# N32G05x register map
Vendor: Nationstech Ltd.; File version: 1.0
Registers are 32-bit, read-write, reset 0x0 unless marked. A register's access mark holds for its fields unless they carry their own. Offsets are from the block's base; [hi:lo] are bit positions; {n}, {i} and the like mark numbered series.

## SPI1 — Serial peripheral interface
Base 0x40012000
Same registers: SPI3 0x40014000, SPI2 0x40014400
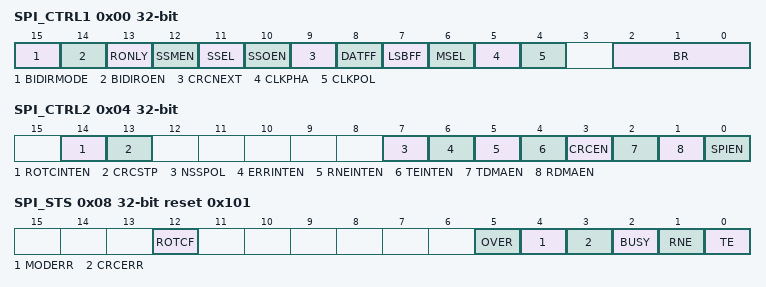
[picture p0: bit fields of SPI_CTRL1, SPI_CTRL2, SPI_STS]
0x00 SPI_CTRL1
  [15] BIDIRMODE
  [14] BIDIROEN
  [13] RONLY
  [12] SSMEN
  [11] SSEL
  [10] SSOEN — SSEL
  [9] CRCNEXT
  [8] DATFF
  [7] LSBFF
  [6] MSEL
  [5] CLKPHA
  [4] CLKPOL
  [2:0] BR
0x04 SPI_CTRL2
  [14] ROTCINTEN, [13] CRCSTP, [7] NSSPOL, [6] ERRINTEN, [5] RNEINTEN, [4] TEINTEN, [3] CRCEN, [2] TDMAEN, [1] RDMAEN, [0] SPIEN
0x08 SPI_STS reset 0x101
  [12] ROTCF, [5] OVER, [4] MODERR, [3] CRCERR, [2] BUSY, [1] RNE, [0] TE
0x0C SPI_DAT
  [15:0] DAT
0x10 SPI_CRCTDAT
  [15:0] CRCTDAT
0x14 SPI_CRCRDAT
  [15:0] CRCRDAT
0x18 SPI_CRCPOLY
  [15:0] CRCPOLY
0x38 SPI_CTRL3
  [3:0] DELAYTIME

## TIM1 — Advanced timer
Base 0x40012C00
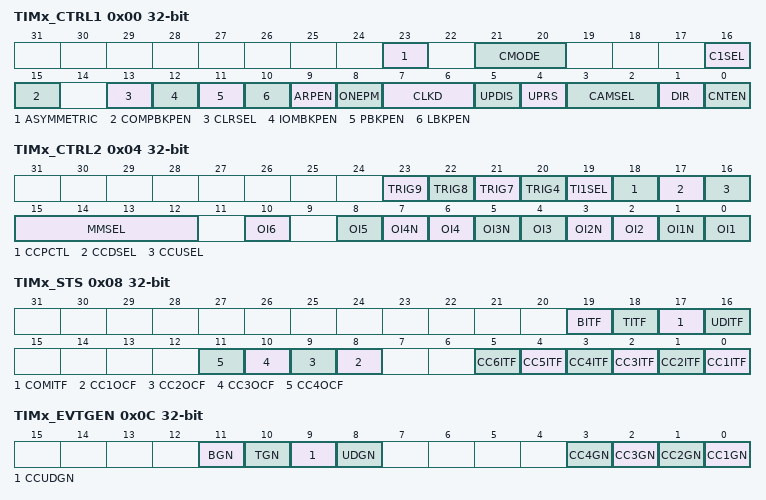
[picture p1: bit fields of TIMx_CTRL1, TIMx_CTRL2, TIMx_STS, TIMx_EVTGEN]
0x00 TIMx_CTRL1 (reset mask 0x38FFF)
  [23] ASYMMETRIC, [21:20] CMODE, [16] C1SEL, [15] COMPBKPEN, [13] CLRSEL, [12] IOMBKPEN, [11] PBKPEN, [10] LBKPEN, [9] ARPEN, [8] ONEPM, [7:6] CLKD, [5] UPDIS, [4] UPRS, [3:2] CAMSEL, [1] DIR, [0] CNTEN
0x04 TIMx_CTRL2 (reset mask 0x57FFD)
  [23] TRIG9, [22] TRIG8, [21] TRIG7, [20] TRIG4, [19] TI1SEL, [18] CCPCTL, [17] CCDSEL, [16] CCUSEL, [15:12] MMSEL, [2n-2] OI{n} (n=1..6), [2n-1] OI{n}N (n=1..4)
0x08 TIMx_STS
  [19] BITF, [18] TITF, [17] COMITF, [16] UDITF, [n+7] CC{n}OCF (n=1..4), [n-1] CC{n}ITF (n=1..6)
0x0C TIMx_EVTGEN
  [11] BGN, [10] TGN, [9] CCUDGN, [8] UDGN, [n-1] CC{n}GN (n=1..4)
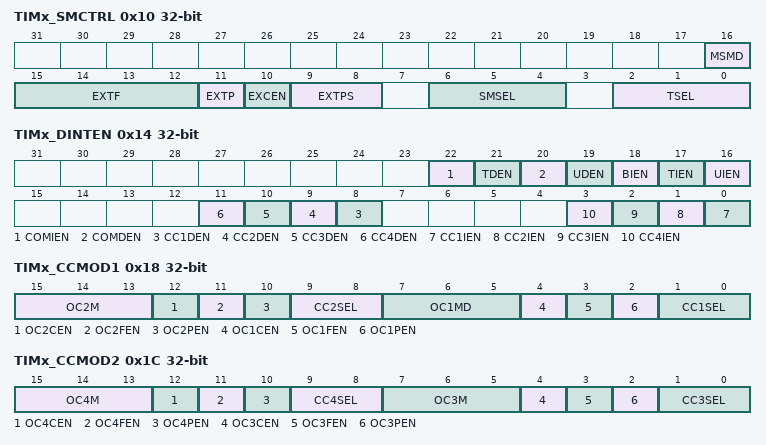
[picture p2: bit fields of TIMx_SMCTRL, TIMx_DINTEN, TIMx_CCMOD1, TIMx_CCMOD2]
0x10 TIMx_SMCTRL
  [16] MSMD, [15:12] EXTF, [11] EXTP, [10] EXCEN, [9:8] EXTPS, [6:4] SMSEL, [2:0] TSEL
0x14 TIMx_DINTEN
  [22] COMIEN, [21] TDEN, [20] COMDEN, [19] UDEN, [18] BIEN, [17] TIEN, [16] UIEN, [n+7] CC{n}DEN (n=1..4), [n-1] CC{n}IEN (n=1..4)
0x18 TIMx_CCMOD1
  [15:13] OC2M
  [12] OC2CEN
  [11] OC2FEN
  [10] OC2PEN
  [9:8] CC2SEL
  [7:5] OC1MD — OC1M
  [4] OC1CEN
  [3] OC1FEN
  [2] OC1PEN
  [1:0] CC1SEL
0x1C TIMx_CCMOD2
  [15:13] OC4M, [12] OC4CEN, [11] OC4FEN, [10] OC4PEN, [9:8] CC4SEL, [7:5] OC3M, [4] OC3CEN, [3] OC3FEN, [2] OC3PEN, [1:0] CC3SEL
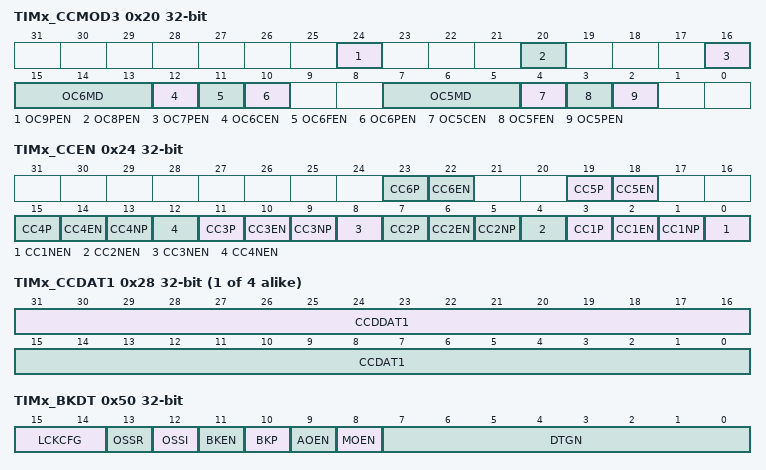
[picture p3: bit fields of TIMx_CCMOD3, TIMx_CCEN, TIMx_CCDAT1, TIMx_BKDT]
0x20 TIMx_CCMOD3
  [24] OC9PEN, [20] OC8PEN, [16] OC7PEN, [15:13] OC6MD, [12] OC6CEN, [11] OC6FEN, [10] OC6PEN, [7:5] OC5MD, [4] OC5CEN, [3] OC5FEN, [2] OC5PEN
0x24 TIMx_CCEN
  [4n-1] CC{n}P (n=1..6), [4n-2] CC{n}EN (n=1..6), [4n-3] CC{n}NP (n=1..4), [4n-4] CC{n}NEN (n=1..4)
{0x24+4i} TIMx_CCDAT{i} (i=1..4)
  [31:16] CCDDAT{i}, [15:0] CCDAT{i}
0x38 TIMx_CCDAT5
  [15:0] CCDAT5
0x3C TIMx_CCDAT6
  [15:0] CCDAT6
0x40 TIMx_PSC
  [15:0] PSC
0x44 TIMx_AR reset 0xFFFF
  [15:0] AR
0x48 TIMx_CNT
  [15:0] CNT
0x4C TIMx_REPCNT
  [7:0] REPCNT
0x50 TIMx_BKDT
  [15:14] LCKCFG, [13] OSSR, [12] OSSI, [11] BKEN, [10] BKP, [9] AOEN, [8] MOEN, [7:0] DTGN
{0x38+4i} TIMx_CCDAT{i} (i=7..9)
  [15:0] CCDAT{i}
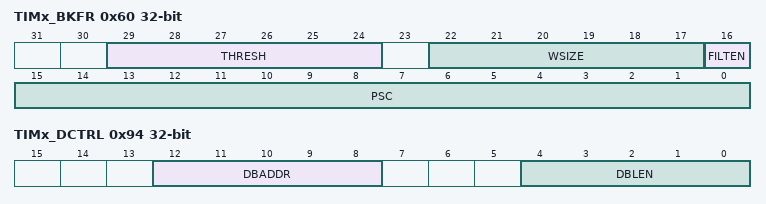
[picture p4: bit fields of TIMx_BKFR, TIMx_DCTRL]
0x60 TIMx_BKFR
  [29:24] THRESH, [22:17] WSIZE, [16] FILTEN, [15:0] PSC
0x94 TIMx_DCTRL
  [12:8] DBADDR, [4:0] DBLEN
0x98 TIMx_DADDR
  [15:0] BURST

## TIM2 — General purpose timer
Base 0x40013400
Same registers: TIM4 0x40012400, TIM5 0x40012800, TIM3 0x40013000
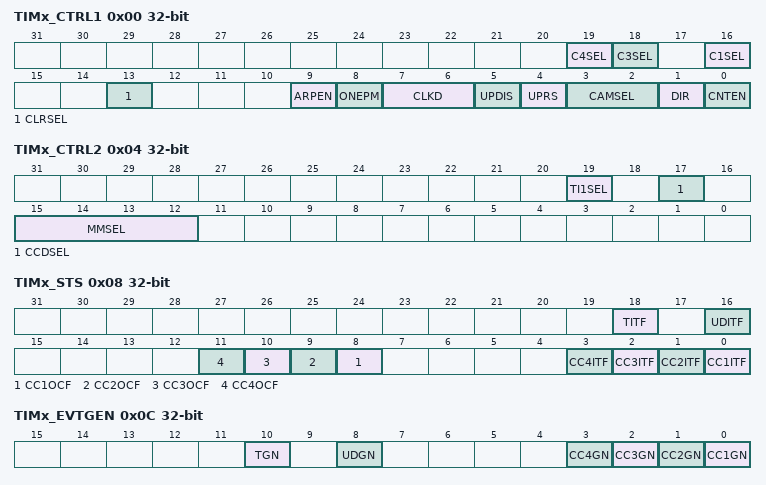
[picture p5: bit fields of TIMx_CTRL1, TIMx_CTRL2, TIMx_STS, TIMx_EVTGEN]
0x00 TIMx_CTRL1
  [19] C4SEL, [18] C3SEL, [16] C1SEL, [13] CLRSEL, [9] ARPEN, [8] ONEPM, [7:6] CLKD, [5] UPDIS, [4] UPRS, [3:2] CAMSEL, [1] DIR, [0] CNTEN
0x04 TIMx_CTRL2
  [19] TI1SEL, [17] CCDSEL, [15:12] MMSEL
0x08 TIMx_STS
  [18] TITF, [16] UDITF, [n+7] CC{n}OCF (n=1..4), [n-1] CC{n}ITF (n=1..4)
0x0C TIMx_EVTGEN
  [10] TGN, [8] UDGN, [n-1] CC{n}GN (n=1..4)
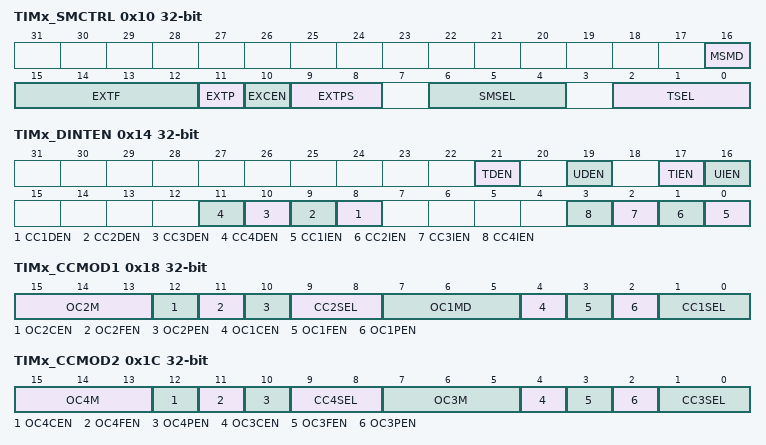
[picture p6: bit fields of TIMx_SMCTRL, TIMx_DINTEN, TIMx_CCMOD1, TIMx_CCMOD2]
0x10 TIMx_SMCTRL
  [16] MSMD, [15:12] EXTF, [11] EXTP, [10] EXCEN, [9:8] EXTPS, [6:4] SMSEL, [2:0] TSEL
0x14 TIMx_DINTEN
  [21] TDEN, [19] UDEN, [17] TIEN, [16] UIEN, [n+7] CC{n}DEN (n=1..4), [n-1] CC{n}IEN (n=1..4)
0x18 TIMx_CCMOD1
  [15:13] OC2M
  [12] OC2CEN
  [11] OC2FEN
  [10] OC2PEN
  [9:8] CC2SEL
  [7:5] OC1MD — OC1M
  [4] OC1CEN
  [3] OC1FEN
  [2] OC1PEN
  [1:0] CC1SEL
0x1C TIMx_CCMOD2
  [15:13] OC4M, [12] OC4CEN, [11] OC4FEN, [10] OC4PEN, [9:8] CC4SEL, [7:5] OC3M, [4] OC3CEN, [3] OC3FEN, [2] OC3PEN, [1:0] CC3SEL
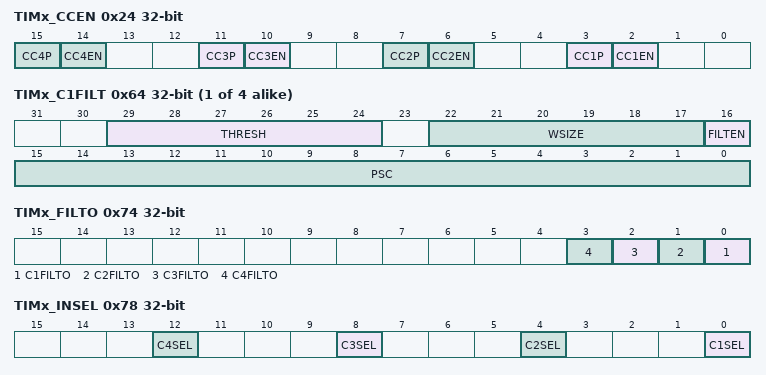
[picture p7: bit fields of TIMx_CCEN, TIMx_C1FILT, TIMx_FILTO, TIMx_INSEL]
0x24 TIMx_CCEN
  [4n-1] CC{n}P (n=1..4), [4n-2] CC{n}EN (n=1..4)
{0x24+4i} TIMx_CCDAT{i} (i=1..4)
  [15:0] CCDAT{i}
0x40 TIMx_PSC
  [15:0] PSC
0x44 TIMx_AR reset 0xFFFF
  [15:0] AR
0x48 TIMx_CNT
  [15:0] CNT
{0x60+4i} TIMx_C{i}FILT (i=1..4)
  [29:24] THRESH, [22:17] WSIZE, [16] FILTEN, [15:0] PSC
0x74 TIMx_FILTO
  [n-1] C{n}FILTO (n=1..4)
0x78 TIMx_INSEL
  [4n-4] C{n}SEL (n=1..4)
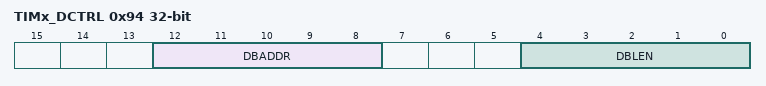
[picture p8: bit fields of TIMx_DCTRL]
0x94 TIMx_DCTRL
  [12:8] DBADDR, [4:0] DBLEN
0x98 TIMx_DADDR
  [15:0] BURST

## TIM6 — Basic timer
Base 0x40001000
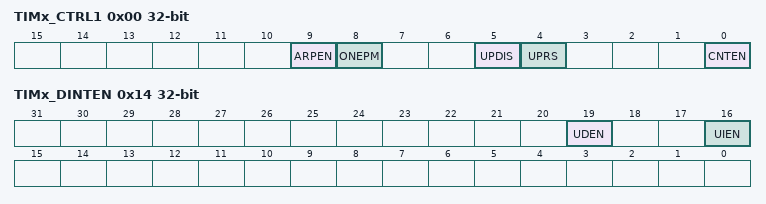
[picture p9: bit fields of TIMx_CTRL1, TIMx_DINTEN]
0x00 TIMx_CTRL1
  [9] ARPEN, [8] ONEPM, [5] UPDIS, [4] UPRS, [0] CNTEN
0x04 TIMx_CTRL2
  [15:12] MMSEL
0x08 TIMx_STS
  [16] UDITF
0x0C TIMx_EVTGEN
  [8] UDGN
0x14 TIMx_DINTEN
  [19] UDEN, [16] UIEN
0x40 TIMx_PSC
  [15:0] PSC
0x44 TIMx_AR reset 0xFFFF
  [15:0] AR
0x48 TIMx_CNT
  [15:0] CNT

## UART1 — Universal asynchronous receiver transmitter
Base 0x40013800
Same registers: UART3 0x40000400, UART4 0x40000800, UART5 0x40000C00, UART2 0x40013C00
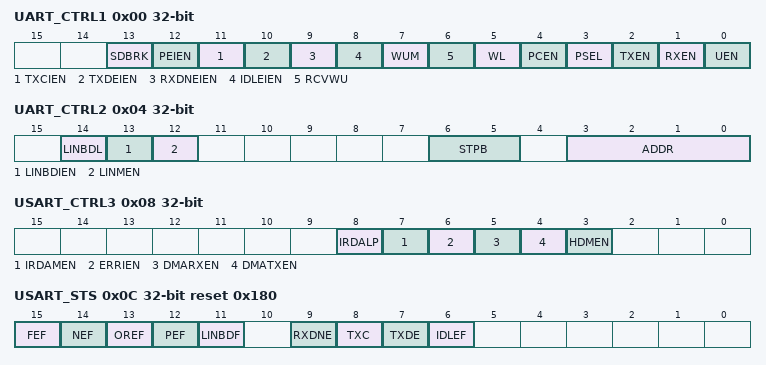
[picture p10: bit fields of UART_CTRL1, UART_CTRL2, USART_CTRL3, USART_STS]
0x00 UART_CTRL1
  [13] SDBRK, [12] PEIEN, [11] TXCIEN, [10] TXDEIEN, [9] RXDNEIEN, [8] IDLEIEN, [7] WUM, [6] RCVWU, [5] WL, [4] PCEN, [3] PSEL, [2] TXEN, [1] RXEN, [0] UEN
0x04 UART_CTRL2 — USART_CTRL2
  [14] LINBDL, [13] LINBDIEN, [12] LINMEN, [6:5] STPB, [3:0] ADDR
0x08 USART_CTRL3
  [8] IRDALP, [7] IRDAMEN, [6] ERRIEN, [5] DMARXEN, [4] DMATXEN, [3] HDMEN
0x0C USART_STS reset 0x180
  [15] FEF, [14] NEF, [13] OREF, [12] PEF, [11] LINBDF, [9] RXDNE, [8] TXC, [7] TXDE, [6] IDLEF
0x10 USART_DAT
  [8:0] DATV
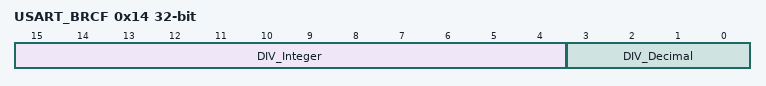
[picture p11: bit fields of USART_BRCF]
0x14 USART_BRCF
  [15:4] DIV_Integer, [3:0] DIV_Decimal
0x18 USART_GTP
  [7:0] PSCV

## WWDG — window watchdog
Base 0x40002C00
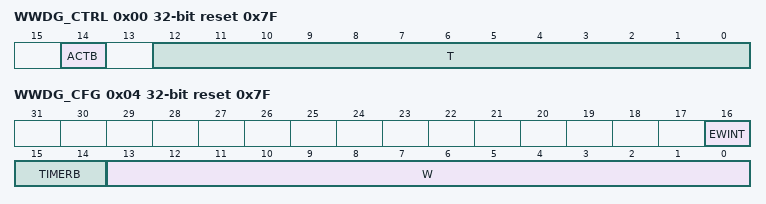
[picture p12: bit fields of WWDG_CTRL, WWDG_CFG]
0x00 WWDG_CTRL reset 0x7F (reset mask 0xFF)
  [14] ACTB, [12:0] T
0x04 WWDG_CFG reset 0x7F (reset mask 0x3FF)
  [16] EWINT, [15:14] TIMERB, [13:0] W
0x08 WWDG_STS
  [0] EWINTF
